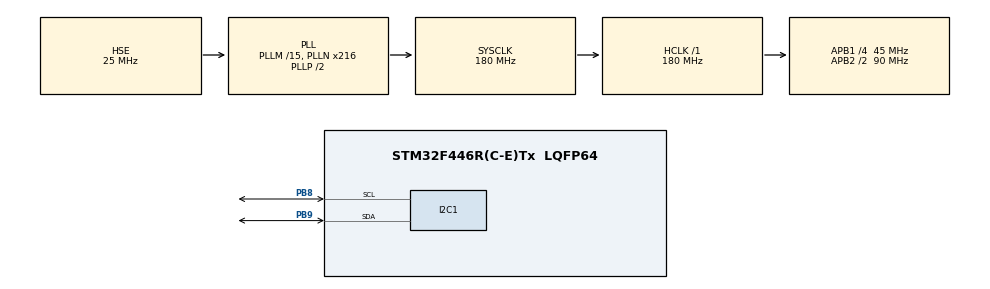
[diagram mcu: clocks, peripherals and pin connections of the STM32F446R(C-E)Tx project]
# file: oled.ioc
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I2C1.I2C_Mode=I2C_Fast
Mcu.Family=STM32F4
Mcu.Name=STM32F446R(C-E)Tx
Mcu.Package=LQFP64
NVIC.PriorityGroup=NVIC_PRIORITYGROUP_4
PB8.Mode=I2C
PB8.Signal=I2C1_SCL
PB9.Mode=I2C
PB9.Signal=I2C1_SDA
PH0-OSC_IN.Mode=HSE-External-Oscillator
PH0-OSC_IN.Signal=RCC_OSC_IN
PH1-OSC_OUT.Mode=HSE-External-Oscillator
PH1-OSC_OUT.Signal=RCC_OSC_OUT
ProjectManager.HeapSize=0x200
ProjectManager.StackSize=0x400
ProjectManager.TargetToolchain=MDK-ARM V5
RCC.AHBFreq_Value=180000000
RCC.APB1CLKDivider=RCC_HCLK_DIV4
RCC.APB1Freq_Value=45000000
RCC.APB1TimFreq_Value=90000000
RCC.APB2CLKDivider=RCC_HCLK_DIV2
RCC.APB2Freq_Value=90000000
RCC.APB2TimFreq_Value=180000000
RCC.CortexFreq_Value=180000000
RCC.HCLKFreq_Value=180000000
RCC.PLLM=15
RCC.PLLN=216
RCC.PLLSourceVirtual=RCC_PLLSOURCE_HSE
RCC.SYSCLKFreq_VALUE=180000000
RCC.SYSCLKSource=RCC_SYSCLKSOURCE_PLLCLK
RCC.USBFreq_Value=180000000
RCC.VCOOutputFreq_Value=360000000
board=oled

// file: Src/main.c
/*
https://www.youtube.com/watch?v=Z6VyFYzQWSs&t=10s
http://controllerstech.com/oled-display-using-i2c-stm32/
*/

#include "main.h"
#include "stm32f4xx_hal.h"

/* USER CODE BEGIN Includes */
#include "ssd1306.h"
#include "i2c-lcd.h"
/* USER CODE END Includes */

I2C_HandleTypeDef hi2c1;

/* USER CODE BEGIN PV */
/* Private variables ---------------------------------------------------------*/

/* USER CODE END PV */

void SystemClock_Config(void);
static void MX_GPIO_Init(void);
static void MX_I2C1_Init(void);

/* USER CODE BEGIN PFP */
/* Private function prototypes -----------------------------------------------*/

/* USER CODE END PFP */

/* USER CODE BEGIN 0 */
uint8_t check;
/* USER CODE END 0 */

int main(void)
{

  /* MCU Configuration----------------------------------------------------------*/

  /* Reset of all peripherals, Initializes the Flash interface and the Systick. */
  HAL_Init();

  /* Configure the system clock */
  SystemClock_Config();

  /* Initialize all configured peripherals */
  MX_GPIO_Init();
  MX_I2C1_Init();
  /* USER CODE BEGIN 2 */
	lcd_init ();
	check = SSD1306_Init ();
	SSD1306_Fill (0);
	SSD1306_UpdateScreen(); //display
	SSD1306_GotoXY (10,3);
	SSD1306_Puts ("  OLED ssd1306", &Font_7x10, 1);
	SSD1306_GotoXY (10, 20);
	SSD1306_Puts ("Prototypes", &Font_11x18, 1);
	SSD1306_UpdateScreen(); //display

	HAL_Delay(1000);

	SSD1306_GotoXY (10, 38);
	SSD1306_Puts ("   Corp.", &Font_11x18, 1);
	SSD1306_UpdateScreen(); //display
	/*

	SSD1306_Fill (0);
	SSD1306_UpdateScreen(); //display
	SSD1306_DrawCircle(20,10,5,1);
	SSD1306_UpdateScreen(); //display
*/
	HAL_Delay(1000);

	//SSD1306_Fill (0);
	//SSD1306_UpdateScreen(); //display
  SSD1306_DrawRectangle(0,0,126,63,1);
  SSD1306_UpdateScreen(); //display

  SSD1306_DrawLine(0,14,126,14,1);
  SSD1306_UpdateScreen(); //display

  SSD1306_DrawLine(0,16,126,16,1);
  SSD1306_UpdateScreen(); //display
	//while((HAL_I2C_IsDeviceReady (&hi2c1, 0x4E, 10, 60)));
	//lcd_send_string ("HELLO !!");

  /* USER CODE END 2 */
  /* Infinite loop */
  while (1)
  {

  }

}

void SystemClock_Config(void)
{

  RCC_OscInitTypeDef RCC_OscInitStruct;
  RCC_ClkInitTypeDef RCC_ClkInitStruct;

    /**Configure the main internal regulator output voltage
    */
  __HAL_RCC_PWR_CLK_ENABLE();

  __HAL_PWR_VOLTAGESCALING_CONFIG(PWR_REGULATOR_VOLTAGE_SCALE1);

    /**Initializes the CPU, AHB and APB busses clocks
    */
  RCC_OscInitStruct.OscillatorType = RCC_OSCILLATORTYPE_HSE;
  RCC_OscInitStruct.HSEState = RCC_HSE_ON;
  RCC_OscInitStruct.PLL.PLLState = RCC_PLL_ON;
  RCC_OscInitStruct.PLL.PLLSource = RCC_PLLSOURCE_HSE;
  RCC_OscInitStruct.PLL.PLLM = 15;
  RCC_OscInitStruct.PLL.PLLN = 216;
  RCC_OscInitStruct.PLL.PLLP = RCC_PLLP_DIV2;
  RCC_OscInitStruct.PLL.PLLQ = 2;
  RCC_OscInitStruct.PLL.PLLR = 2;
  if (HAL_RCC_OscConfig(&RCC_OscInitStruct) != HAL_OK)
  {
    _Error_Handler(__FILE__, __LINE__);
  }

    /**Activate the Over-Drive mode
    */
  if (HAL_PWREx_EnableOverDrive() != HAL_OK)
  {
    _Error_Handler(__FILE__, __LINE__);
  }

    /**Initializes the CPU, AHB and APB busses clocks
    */
  RCC_ClkInitStruct.ClockType = RCC_CLOCKTYPE_HCLK|RCC_CLOCKTYPE_SYSCLK
                              |RCC_CLOCKTYPE_PCLK1|RCC_CLOCKTYPE_PCLK2;
  RCC_ClkInitStruct.SYSCLKSource = RCC_SYSCLKSOURCE_PLLCLK;
  RCC_ClkInitStruct.AHBCLKDivider = RCC_SYSCLK_DIV1;
  RCC_ClkInitStruct.APB1CLKDivider = RCC_HCLK_DIV4;
  RCC_ClkInitStruct.APB2CLKDivider = RCC_HCLK_DIV2;

  if (HAL_RCC_ClockConfig(&RCC_ClkInitStruct, FLASH_LATENCY_5) != HAL_OK)
  {
    _Error_Handler(__FILE__, __LINE__);
  }

    /**Configure the Systick interrupt time
    */
  HAL_SYSTICK_Config(HAL_RCC_GetHCLKFreq()/1000);

    /**Configure the Systick
    */
  HAL_SYSTICK_CLKSourceConfig(SYSTICK_CLKSOURCE_HCLK);

  /* SysTick_IRQn interrupt configuration */
  HAL_NVIC_SetPriority(SysTick_IRQn, 0, 0);
}

/* I2C1 init function */
static void MX_I2C1_Init(void)
{

  hi2c1.Instance = I2C1;
  hi2c1.Init.ClockSpeed = 400000;
  hi2c1.Init.DutyCycle = I2C_DUTYCYCLE_2;
  hi2c1.Init.OwnAddress1 = 0;
  hi2c1.Init.AddressingMode = I2C_ADDRESSINGMODE_7BIT;
  hi2c1.Init.DualAddressMode = I2C_DUALADDRESS_DISABLE;
  hi2c1.Init.OwnAddress2 = 0;
  hi2c1.Init.GeneralCallMode = I2C_GENERALCALL_DISABLE;
  hi2c1.Init.NoStretchMode = I2C_NOSTRETCH_DISABLE;
  if (HAL_I2C_Init(&hi2c1) != HAL_OK)
  {
    _Error_Handler(__FILE__, __LINE__);
  }

}

/** Configure pins as
        * Analog
        * Input
        * Output
        * EVENT_OUT
        * EXTI
*/
static void MX_GPIO_Init(void)
{

  /* GPIO Ports Clock Enable */
  __HAL_RCC_GPIOH_CLK_ENABLE();
  __HAL_RCC_GPIOB_CLK_ENABLE();

}

void _Error_Handler(char *file, int line)
{
  while(1)
  {
  }
}

/************************ (C) COPYRIGHT STMicroelectronics *****END OF FILE****/
